# PIC32MK0512GPE100 register map
Vendor: Microchip
Registers are 32-bit, read-write, reset 0x0 unless marked. A register's access mark holds for its fields unless they carry their own. Addresses are absolute, and some are shared; only a register's first bit layout is shown; [hi:lo] are bit positions; {n}, {i} and the like mark numbered series.

## CAN2
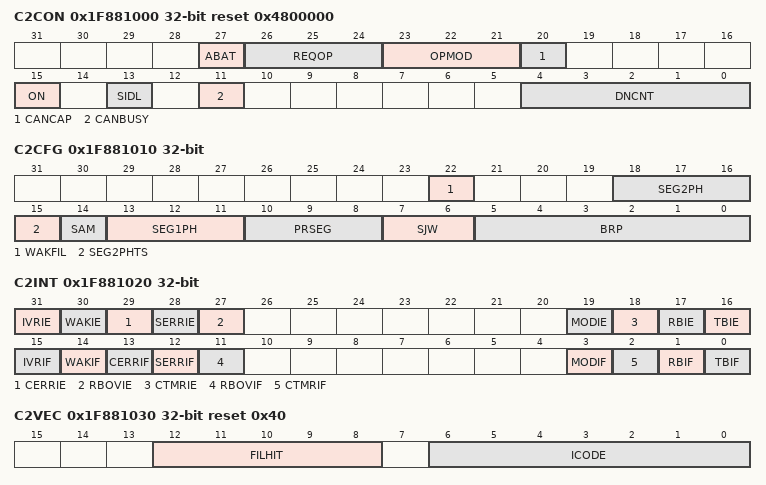
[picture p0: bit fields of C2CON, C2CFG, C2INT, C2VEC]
0x1F881000 C2CON reset 0x4800000
  [27] ABAT — (can only be set)
  [26:24] REQOP
  [23:21] OPMOD ro
  [20] CANCAP
  [15] ON
  [13] SIDL
  [11] CANBUSY ro
  [4:0] DNCNT
0x1F881010 C2CFG
  [22] WAKFIL, [18:16] SEG2PH, [15] SEG2PHTS, [14] SAM, [13:11] SEG1PH, [10:8] PRSEG, [7:6] SJW, [5:0] BRP
0x1F881020 C2INT
  [31] IVRIE, [30] WAKIE, [29] CERRIE, [28] SERRIE, [27] RBOVIE, [19] MODIE, [18] CTMRIE, [17] RBIE, [16] TBIE, [15] IVRIF, [14] WAKIF, [13] CERRIF, [12] SERRIF, [11] RBOVIF, [3] MODIF, [2] CTMRIF, [1] RBIF, [0] TBIF
0x1F881030 C2VEC ro reset 0x40
  [12:8] FILHIT, [6:0] ICODE
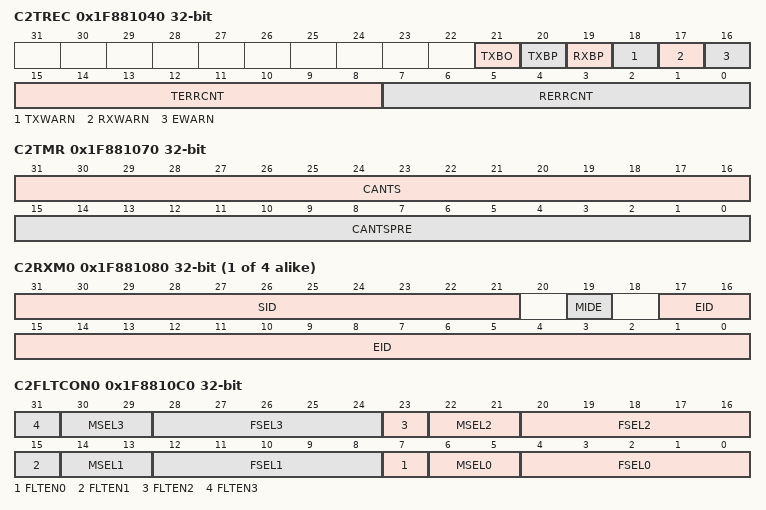
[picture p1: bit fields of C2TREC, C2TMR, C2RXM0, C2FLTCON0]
0x1F881040 C2TREC ro
  [21] TXBO, [20] TXBP, [19] RXBP, [18] TXWARN, [17] RXWARN, [16] EWARN, [15:8] TERRCNT, [7:0] RERRCNT
0x1F881050 C2FSTAT ro
  [15:0] FIFOIP
0x1F881060 C2RXOVF ro
  [15:0] RXOVF
0x1F881070 C2TMR
  [31:16] CANTS, [15:0] CANTSPRE
{0x1F881080+0x10*i} C2RXM{i} (i=0..3)
  [31:21] SID, [19] MIDE, [17:0] EID
0x1F8810C0 C2FLTCON0
  [8n+7] FLTEN{n} (n=0..3), [8n+6:8n+5] MSEL{n} (n=0..3), [8n+4:8n] FSEL{n} (n=0..3)
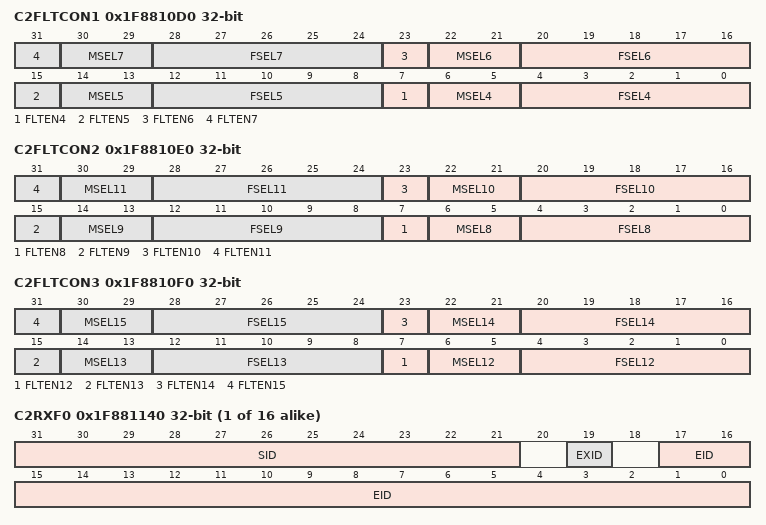
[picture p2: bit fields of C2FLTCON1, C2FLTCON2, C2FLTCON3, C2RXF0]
0x1F8810D0 C2FLTCON1
  [8n-25] FLTEN{n} (n=4..7), [8n-26:8n-27] MSEL{n} (n=4..7), [8n-28:8n-32] FSEL{n} (n=4..7)
0x1F8810E0 C2FLTCON2
  [8n-57] FLTEN{n} (n=8..11), [8n-58:8n-59] MSEL{n} (n=8..11), [8n-60:8n-64] FSEL{n} (n=8..11)
0x1F8810F0 C2FLTCON3
  [8n-89] FLTEN{n} (n=12..15), [8n-90:8n-91] MSEL{n} (n=12..15), [8n-92:8n-96] FSEL{n} (n=12..15)
{0x1F881140+0x10*i} C2RXF{i} reset not defined (i=0..15) — (power-on value xxxxxxxxxxx0x0xxxxxxxxxxxxxxxxxx)
  [31:21] SID, [19] EXID, [17:0] EID
0x1F881340 C2FIFOBA
  [31:2] FIFOBA
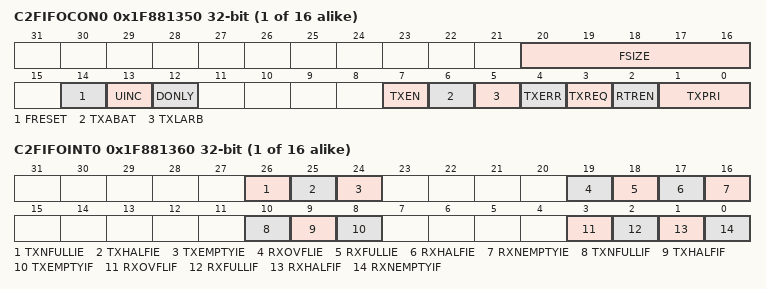
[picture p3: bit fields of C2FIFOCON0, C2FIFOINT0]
{0x1F881350+0x40*i} C2FIFOCON{i} (i=0..15)
  [20:16] FSIZE, [14] FRESET, [13] UINC, [12] DONLY, [7] TXEN, [6] TXABAT, [5] TXLARB, [4] TXERR, [3] TXREQ, [2] RTREN, [1:0] TXPRI
{0x1F881360+0x40*i} C2FIFOINT{i} (i=0..15)
  [26] TXNFULLIE, [25] TXHALFIE, [24] TXEMPTYIE, [19] RXOVFLIE, [18] RXFULLIE, [17] RXHALFIE, [16] RXNEMPTYIE, [10] TXNFULLIF ro, [9] TXHALFIF ro, [8] TXEMPTYIF ro, [3] RXOVFLIF, [2] RXFULLIF ro, [1] RXHALFIF ro, [0] RXNEMPTYIF ro
{0x1F881370+0x40*i} C2FIFOUA{i} ro reset not defined (i=0..15) — (power-on value xxxxxxxxxxxxxxxxxxxxxxxxxxxxxx00)
  [31:2] FIFOUA
{0x1F881380+0x40*i} C2FIFOCI{i} ro (i=0..15)
  [4:0] CFIFOCI

## CAN3
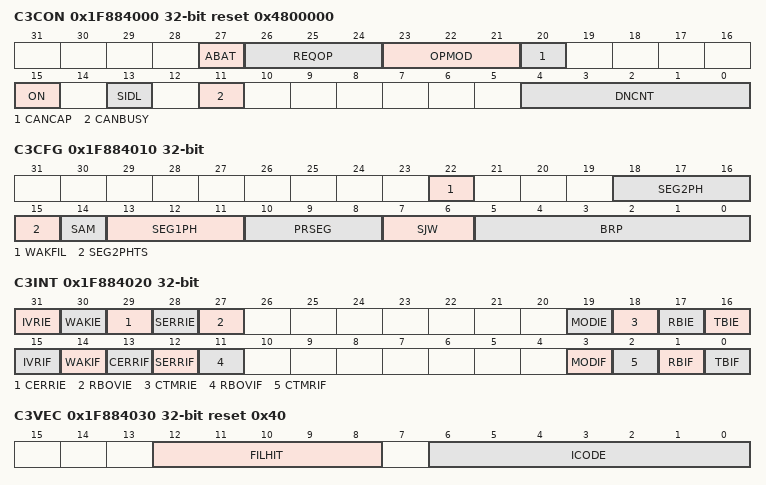
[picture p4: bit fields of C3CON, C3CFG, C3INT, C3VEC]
0x1F884000 C3CON reset 0x4800000
  [27] ABAT — (can only be set)
  [26:24] REQOP
  [23:21] OPMOD ro
  [20] CANCAP
  [15] ON
  [13] SIDL
  [11] CANBUSY ro
  [4:0] DNCNT
0x1F884010 C3CFG
  [22] WAKFIL, [18:16] SEG2PH, [15] SEG2PHTS, [14] SAM, [13:11] SEG1PH, [10:8] PRSEG, [7:6] SJW, [5:0] BRP
0x1F884020 C3INT
  [31] IVRIE, [30] WAKIE, [29] CERRIE, [28] SERRIE, [27] RBOVIE, [19] MODIE, [18] CTMRIE, [17] RBIE, [16] TBIE, [15] IVRIF, [14] WAKIF, [13] CERRIF, [12] SERRIF, [11] RBOVIF, [3] MODIF, [2] CTMRIF, [1] RBIF, [0] TBIF
0x1F884030 C3VEC ro reset 0x40
  [12:8] FILHIT, [6:0] ICODE
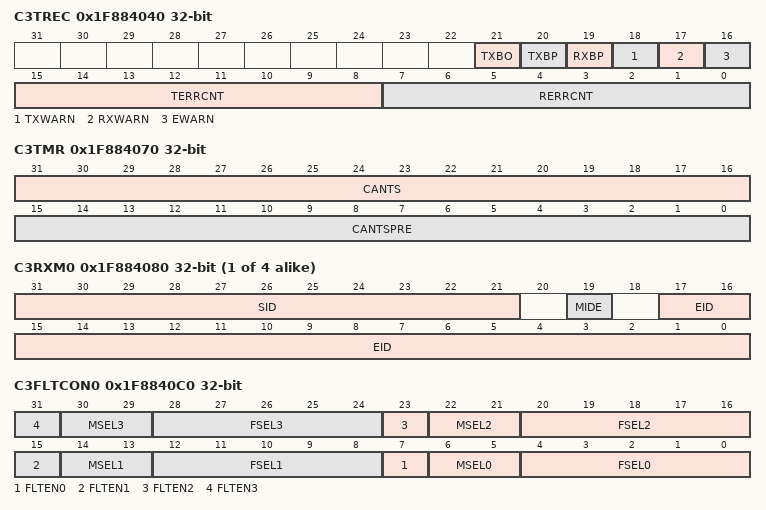
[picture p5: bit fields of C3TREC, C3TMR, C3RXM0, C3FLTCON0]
0x1F884040 C3TREC ro
  [21] TXBO, [20] TXBP, [19] RXBP, [18] TXWARN, [17] RXWARN, [16] EWARN, [15:8] TERRCNT, [7:0] RERRCNT
0x1F884050 C3FSTAT ro
  [15:0] FIFOIP
0x1F884060 C3RXOVF ro
  [15:0] RXOVF
0x1F884070 C3TMR
  [31:16] CANTS, [15:0] CANTSPRE
{0x1F884080+0x10*i} C3RXM{i} (i=0..3)
  [31:21] SID, [19] MIDE, [17:0] EID
0x1F8840C0 C3FLTCON0
  [8n+7] FLTEN{n} (n=0..3), [8n+6:8n+5] MSEL{n} (n=0..3), [8n+4:8n] FSEL{n} (n=0..3)
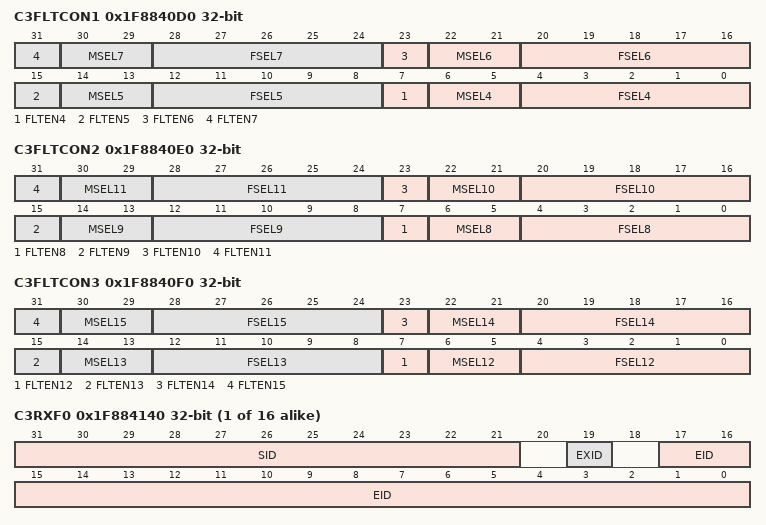
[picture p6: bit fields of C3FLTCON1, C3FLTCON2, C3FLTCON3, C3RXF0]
0x1F8840D0 C3FLTCON1
  [8n-25] FLTEN{n} (n=4..7), [8n-26:8n-27] MSEL{n} (n=4..7), [8n-28:8n-32] FSEL{n} (n=4..7)
0x1F8840E0 C3FLTCON2
  [8n-57] FLTEN{n} (n=8..11), [8n-58:8n-59] MSEL{n} (n=8..11), [8n-60:8n-64] FSEL{n} (n=8..11)
0x1F8840F0 C3FLTCON3
  [8n-89] FLTEN{n} (n=12..15), [8n-90:8n-91] MSEL{n} (n=12..15), [8n-92:8n-96] FSEL{n} (n=12..15)
{0x1F884140+0x10*i} C3RXF{i} reset not defined (i=0..15) — (power-on value xxxxxxxxxxx0x0xxxxxxxxxxxxxxxxxx)
  [31:21] SID, [19] EXID, [17:0] EID
0x1F884340 C3FIFOBA
  [31:2] FIFOBA
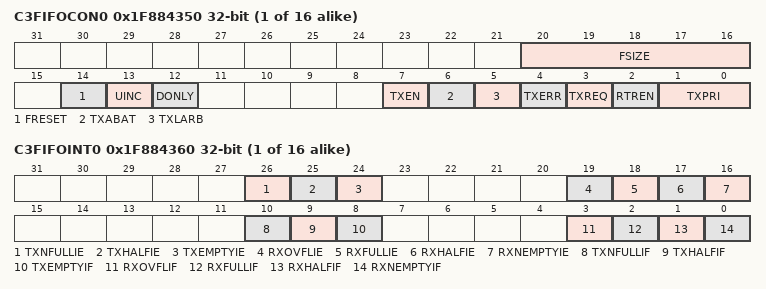
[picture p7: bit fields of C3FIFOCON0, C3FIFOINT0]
{0x1F884350+0x40*i} C3FIFOCON{i} (i=0..15)
  [20:16] FSIZE, [14] FRESET, [13] UINC, [12] DONLY, [7] TXEN, [6] TXABAT, [5] TXLARB, [4] TXERR, [3] TXREQ, [2] RTREN, [1:0] TXPRI
{0x1F884360+0x40*i} C3FIFOINT{i} (i=0..15)
  [26] TXNFULLIE, [25] TXHALFIE, [24] TXEMPTYIE, [19] RXOVFLIE, [18] RXFULLIE, [17] RXHALFIE, [16] RXNEMPTYIE, [10] TXNFULLIF ro, [9] TXHALFIF ro, [8] TXEMPTYIF ro, [3] RXOVFLIF, [2] RXFULLIF ro, [1] RXHALFIF ro, [0] RXNEMPTYIF ro
{0x1F884370+0x40*i} C3FIFOUA{i} ro reset not defined (i=0..15) — (power-on value xxxxxxxxxxxxxxxxxxxxxxxxxxxxxx00)
  [31:2] FIFOUA
{0x1F884380+0x40*i} C3FIFOCI{i} ro (i=0..15)
  [4:0] CFIFOCI
